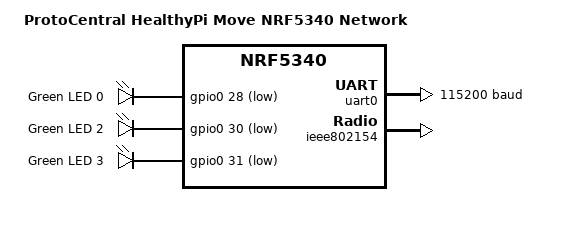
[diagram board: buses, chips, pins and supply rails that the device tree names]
/*
 * Copyright (c) 2020 Nordic Semiconductor ASA
 *
 * SPDX-License-Identifier: Apache-2.0
 */

/dts-v1/;
#include <nordic/nrf5340_cpunet_qkaa.dtsi>
#include "healthypi_move_nrf5340_cpunet-pinctrl.dtsi"
#include <zephyr/dt-bindings/input/input-event-codes.h>

/ {
	model = "ProtoCentral HealthyPi Move NRF5340 Network";
	compatible = "protocentral,healthypi-move-nrf5340-cpunet";

	chosen {
		zephyr,console = &uart0;
		zephyr,shell-uart = &uart0;
		zephyr,uart-mcumgr = &uart0;
		zephyr,bt-mon-uart = &uart0;
		zephyr,bt-c2h-uart = &uart0;
		zephyr,bt-hci-ipc = &ipc0;
		nordic,802154-spinel-ipc = &ipc0;

		zephyr,sram = &sram1;
		zephyr,flash = &flash1;
		zephyr,code-partition = &slot0_partition;
		zephyr,ieee802154 = &ieee802154;
	};

	leds {
		compatible = "gpio-leds";
		led0: led_0 {
			gpios = <&gpio0 28 GPIO_ACTIVE_LOW>;
			label = "Green LED 0";
		};
		
		led2: led_2 {
			gpios = <&gpio0 30 GPIO_ACTIVE_LOW>;
			label = "Green LED 2";
		};
		led3: led_3 {
			gpios = <&gpio0 31 GPIO_ACTIVE_LOW>;
			label = "Green LED 3";
		};
	};

	/* These aliases are provided for compatibility with samples */
	aliases {
		led0 = &led0;
		
		led2 = &led2;
		led3 = &led3;

		bootloader-led0 = &led0;
		//mcuboot-button0 = &button0;
		mcuboot-led0 = &led0;
		watchdog0 = &wdt0;
	};
};

&gpiote {
	status = "okay";
};

&gpio0 {
	status = "okay";
};

&gpio1 {
	status = "okay";
};

&uart0 {
	status = "okay";
	current-speed = <115200>;
	pinctrl-0 = <&uart0_default>;
	pinctrl-1 = <&uart0_sleep>;
	pinctrl-names = "default", "sleep";
};

arduino_serial: &uart0{};

arduino_i2c: &i2c0 {
	compatible = "nordic,nrf-twim";
	/* Cannot be used together with uart0. */
	/* status = "okay"; */
	pinctrl-0 = <&i2c0_default>;
	pinctrl-1 = <&i2c0_sleep>;
	pinctrl-names = "default", "sleep";
};

&flash1 {

	/*
	 * M3: PM->DTS. Net core uses NSIB secure boot (b0n) + a single app slot,
	 * matching the previous PM-resolved layout. b0n boots s0_partition; net
	 * updates arrive via the app-core external staging and PCD.
	 */
	partitions {
		compatible = "fixed-partitions";
		#address-cells = <1>;
		#size-cells = <1>;

		/* Net-core immutable secure bootloader (NSIB / b0n). */
		b0n_partition: partition@0 {
			label = "b0n";
			reg = <0x00000000 0x00008580>;
		};

		/* b0n provisioning data (bl_storage label required by NSIB). */
		bl_storage: provision_partition: partition@8580 {
			label = "b0n-provision";
			reg = <0x00008580 0x00000280>;
		};

		/* Net-core application slot (booted by b0n). */
		s0_partition: partition@8800 {
			label = "image-0";
			reg = <0x00008800 0x00037800>;
		};
	};
};

&ieee802154 {
	status = "okay";
};

/* Include default shared RAM configuration file */
#include <nordic/nrf5340_shared_sram_partition.dtsi>
